AUTOSAR XML (schema 00048)
package /ComponentTypes
  swc implementation RTC_Implementation: behavior=RTC_InternalBehavior
    code-descriptors:
      code Default: artifact-descriptors=autosar-engineering-object=category=SWSRC
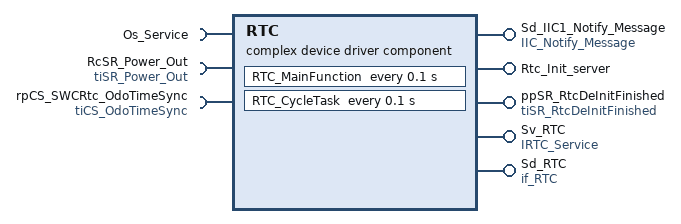
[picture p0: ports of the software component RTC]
  complex device driver sw component type RTC
    provide port Sd_IIC1_Notify_Message: queued-sender-com-spec=Message, provided-interface=IIC_Notify_Message
    require port Os_Service: required-com-specs=[GetElapsedValue, GetCounterValue], required-interface=Os_Service
    4 x provide port:
      Rtc_Init_server: server-com-spec{operation=Operation, queue-length=1}, provided-interface=Rtc_Init_server
      ppSR_RtcDeInitFinished: nonqueued-sender-com-spec{data-element=State, init-value=0}, provided-interface=tiSR_RtcDeInitFinished
      Sv_RTC: provided-com-specs=[{operation=UTC2PerpetualCalendar, queue-length=1}, {operation=GetUTCTimeInMillis, queue-length=1}], provided-interface=IRTC_Service
      Sd_RTC: provided-com-specs=[{data-element=UtcTime, init-value=-1}, {data-element=SleepDateTime, init-value=-1}], provided-interface=if_RTC
    require port RcSR_Power_Out: nonqueued-receiver-com-spec{data-element=SystemStateOut, filter=data-filter-type=ALWAYS, init-value=constant-reference=PowerOutInit}, required-interface=tiSR_Power_Out
    require port rpCS_SWCRtc_OdoTimeSync: client-com-spec=CallBack, required-interface=tiCS_OdoTimeSync
    behavior RTC_InternalBehavior
      exclusive area ExclusiveArea_RTC
      timing event TMT_RTC_MainFunction: start-on-event=RTC_MainFunction, period=0.1
      timing event TMT_RTC_CycleTask: start-on-event=RTC_CycleTask, period=0.1
      operation invoked event OIT_Rtc_Init_server_Operation_Rtc_Init_server_Operation: start-on-event=RTC_Init, operation=Rtc_Init_server.Operation
      operation invoked event OIT_UTC2PerpetualCalendar_Sv_RTC_UTC2PerpetualCalendar: start-on-event=UTC2PerpetualCalendar, operation=Sv_RTC.UTC2PerpetualCalendar
      operation invoked event OIT_GetUTCTimeInMillis_Sv_RTC_GetUTCTimeInMillis: start-on-event=GetUTCTimeInMillis, operation=Sv_RTC.GetUTCTimeInMillis
      port-api-options:
        enable-take-address=true, error-handling=NO-TRANSFORMER-ERROR-HANDLING, indirect-api=false, port=Rtc_Init_server
        enable-take-address=true, error-handling=NO-TRANSFORMER-ERROR-HANDLING, indirect-api=false, port=Sv_RTC
      5 x runnable:
        RTC_MainFunction: can-enter-exclusive-area=ExclusiveArea_RTC
          data-receive-point-by-arguments:
            access REC_RcSR_Power_Out_SystemStateOut: accessed-variable=RcSR_Power_Out.SystemStateOut
          data-send-points:
            access SEND_Sd_IIC1_Notify_Message_Message: accessed-variable=Sd_IIC1_Notify_Message.Message
          sync call SC_Os_Service_GetCounterValue: operation=Os_Service.GetCounterValue
          sync call SC_Os_Service_GetElapsedValue: operation=Os_Service.GetElapsedValue
          sync call SC_rpCS_SWCRtc_OdoTimeSync_CallBack: operation=rpCS_SWCRtc_OdoTimeSync.CallBack
        RTC_CycleTask
          data-send-points:
            access SEND_Sd_RTC_UtcTime: accessed-variable=Sd_RTC.UtcTime
            access SEND_Sd_RTC_SleepDateTime: accessed-variable=Sd_RTC.SleepDateTime
        RTC_Init
        UTC2PerpetualCalendar: can-be-invoked-concurrently=true, symbol=RTC_UTC2PerpetualCalendar
        GetUTCTimeInMillis: symbol=RTC_GetUTCTimeInMillis
